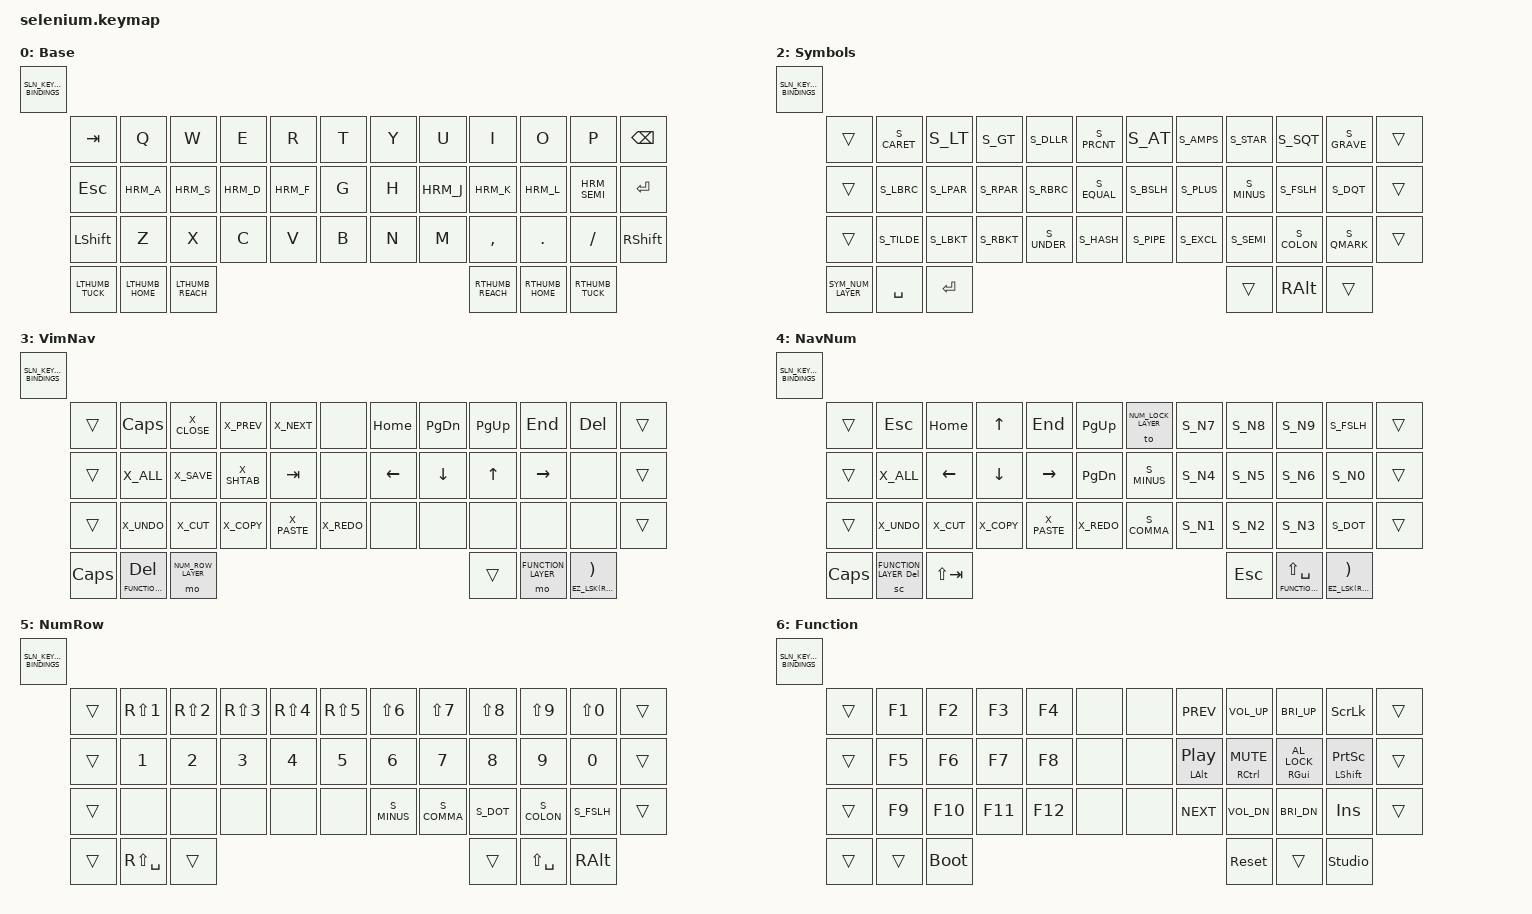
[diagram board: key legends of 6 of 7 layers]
// Selenium keymap:
// https://github.com/OneDeadKey/selenium


/******************************************************************************
 * Layout-specific actions and symbols.
******************************************************************************/

// Uncomment one of the folowing lines if using a non-QWERTY layout:

// #define KB_LAYOUT_QWERTY_LAFAYETTE
// #define KB_LAYOUT_AZERTY
// #define KB_LAYOUT_ERGOL

// Uncomment the folowing line if using a Mac:

// #define MACOS


/******************************************************************************
 * Hold-Taps
******************************************************************************/

// Uncomment one of the folowing lines to pick your preferred hold-tap config:

// #define HT_NONE
// #define HT_THUMB_TAPS
// #define HT_HOME_ROW_MODS  // (default behavior)
// #define HT_TWO_THUMB_KEYS

// Timing is key! Keep the default value if unsure.
// This defines how long (in ms) a hold-tap key with the "tap-preferred" flavor
// must be held to be considered as a modifier or layer shift. These hold-taps
// are the ones that may produce text, including the space-bar and home-row-mods.
// Keep this value high if you struggle wih home-row-mods.

// #define TAPPING_TERM 300

// This defines how quickly (in ms) you need to press and release a hold-tap
// with the "hold-preferred" flavor for it to be considered a tap. These
// hold-taps include the ones that don’t produce text when tapped.
// Keep this value low if you press Enter or Escape by mistake too often.

// #define SHORT_TAPPING_TERM 150

// When tapping then holding the same tap-hold, if the delay between the two
// key presses is lower than `QUICK_TAP`, the tap-hold will hold the tap action
// instead of the hold action. Again, keep the default value if unsure.

// #define QUICK_TAP 200

// For more information on how hold-taps operate, feel free to read ZMK’s docs:
// https://zmk.dev/docs/keymaps/behaviors/hold-tap

/******************************************************************************
 * Other Options
*****************************************************************************/

// Uncomment the following line to plit the num-nav layer in two:
//  - one layer for vim-style navigation (right) and GUI shortcuts (left)
//  - one layer for a full number row + easy access to Shift+Number
//  + Escape under the left thumb (direct access)
// Highly recommended for Vim users, obviously. :-)

// #define VIM_NAVIGATION

// Uncomment the following line to enable shift as a pinky HRM.
// Useful for combined shortcuts, but NOT MEANT to type text!

// #define HRM_SHIFT

// Uncomment the following line to swap Space and Backspace.
// Beware: this increases the typing load of the left thumb.

// #define LEFT_HAND_SPACE


/******************************************************************************
 * Keymap
******************************************************************************/

#include "aliases.h"      // defines symbols and actions
#include "hold_taps.dtsi" // defines thumb keys and homerow mods

/**
 * All keyboard layouts are defined on a 42-key basis, as follows:
 *
 *   Tab   , QWERT , YUIOP , Backspace           LOUT1,  LROW1,  RROW1,  ROUT1
 *   Esc   , ASDFG , HJKL: , Enter        =>     LOUT2,  LROW2,  RROW2,  ROUT2
 *   Shift , ZXCVB , NM<>? , Shift               LOUT3,  LROW3,  RROW3,  ROUT3
 *    LT1, LT2, LT3, RT3, RT2, RT1               LT1, LT2, LT3,  RT3, RT2, RT1
 *
 * Where:
 *
 *   LROW[1-3], RROW[1-3]: keys on the left/right main rows (usually letter/punctuation keys)
 *   LOUT[1-3], ROUT[1-3]: keys on the left/right outer columns (usually special keys)
 *     LT[1-3],   RT[1-3]: keys on the left/right thumb clusters (usually Space or modifiers/layers)
 *
 * Beware: misplacing a comma in the definitions below would break the keymap.
 */

// This macro can be overridden in keymaps if needed.
// Selenium by default only offers keymaps for 3x5 or 3x6 keyboards.
// Redefining this macro allows to add more rows or more columns to the keymap,
// or to add keys between the 2 halves if needed.
#ifndef SLN_KEYMAP_BINDINGS
#define SLN_KEYMAP_BINDINGS(LOUT1,  LROW1,  RROW1,  ROUT1, \
                            LOUT2,  LROW2,  RROW2,  ROUT2, \
                            LOUT3,  LROW3,  RROW3,  ROUT3, \
                            LT1, LT2, LT3,  RT3, RT2, RT1) \
    LOUT1 LROW1 RROW1 ROUT1 \
    LOUT2 LROW2 RROW2 ROUT2 \
    LOUT3 LROW3 RROW3 ROUT3 \
    LT1 LT2 LT3 RT3 RT2 RT1
#endif

/ {
  keymap {
    compatible = "zmk,keymap";

    // 0. Base layer -- keep the QWERTY key codes to use your OS keyboard layout
    //               -- the Space Cadet layer-tap on the right can be replaced by an AltGr/Enter mod-tap
    //               -- adjust the homerow mods with the #define statements above
    base_layer: base_layer {
      display-name = "Base";
      bindings = <SLN_KEYMAP_BINDINGS(                                                                                     \
        &kp TAB    ,  &kp Q  &kp W  &kp E  &kp R  &kp T   ,   &kp Y  &kp U  &kp I     &kp O   &kp P     ,  &kp BACKSPACE , \
        &kp ESCAPE ,  HRM_A  HRM_S  HRM_D  HRM_F  &kp G   ,   &kp H  HRM_J  HRM_K     HRM_L   HRM_SEMI  ,  &kp ENTER     , \
        &kp LSHIFT ,  &kp Z  &kp X  &kp C  &kp V  &kp B   ,   &kp N  &kp M  &kp COMMA &kp DOT &kp FSLH  ,  &kp RSHIFT    , \
               LTHUMB_TUCK , LTHUMB_HOME , LTHUMB_REACH   ,   RTHUMB_REACH , RTHUMB_HOME , RTHUMB_TUCK                     \
      )>;
    };

    // 1. NumLock layer -- NavNum layer that stays on until deactivated without holding key
    num_lock_layer: num_lock_layer {
      display-name = "NumLock";
      bindings = <SLN_KEYMAP_BINDINGS(
        &trans  ,  &kp ESC  &kp HOME &kp UP   &kp END   &kp PG_UP   ,   &to BASE_LAYER S_N7  S_N8  S_N9  S_FSLH  ,  &trans ,
        &trans  ,  S_EQUAL  &kp LEFT &kp DOWN &kp RIGHT &kp PG_DN   ,   S_MINUS        S_N4  S_N5  S_N6  S_N0    ,  &trans ,
        &trans  ,  S_MONEY  S_COLON  S_STAR   S_PLUS    S_PRCNT     ,   S_COMMA        S_N1  S_N2  S_N3  S_DOT   ,  &trans ,
                 &trans , &sc NUM_NAV_LAYER BACKSPACE , &kp (TAB)   ,   &trans , &lt NUM_NAV_LAYER LS(SPACE) , &EZ_SL(SYMBOLS_LAYER)
      )>;
    };

    // 2. Symbols layer -- with Ergol, basically just an AltGr layer with custom thumb keys
    //                  -- can be redefined for non-AltGr layouts such as QWERTY-ANSI
    symbols_layer: symbols_layer {
      display-name = "Symbols";
      bindings = <SLN_KEYMAP_BINDINGS(
        &trans  ,  S_CARET S_LT    S_GT    S_DLLR  S_PRCNT   ,   S_AT    S_AMPS  S_STAR  S_SQT   S_GRAVE  ,  &trans ,
        &trans  ,  S_LBRC  S_LPAR  S_RPAR  S_RBRC  S_EQUAL   ,   S_BSLH  S_PLUS  S_MINUS S_FSLH  S_DQT    ,  &trans ,
        &trans  ,  S_TILDE S_LBKT  S_RBKT  S_UNDER S_HASH    ,   S_PIPE  S_EXCL  S_SEMI  S_COLON S_QMARK  ,  &trans ,
                     SYM_NUM_LAYER , &kp SPACE , &kp ENTER   ,   &trans ,  &kp RALT ,  &trans
      )>;
    };

    // 3. VimNav layer -- HJKL arrow cluster on the right hand
    //                 -- best used along with the NumRow layer
    //                 -- keyboard shortcuts on the left hand are adjusted to the OS layout (Ergol here)
    vim_nav_layer: vim_nav_layer {
      display-name = "VimNav";
      bindings = <SLN_KEYMAP_BINDINGS(
        &trans  ,  &kp CAPS X_CLOSE  X_PREV   X_NEXT    &none     ,   &kp HOME &kp PG_DN &kp PG_UP &kp END   &kp DEL ,  &trans ,
        &trans  ,  X_ALL    X_SAVE   X_SHTAB  &kp TAB   &none     ,   &kp LEFT &kp DOWN  &kp UP    &kp RIGHT &none   ,  &trans ,
        &trans  ,  X_UNDO   X_CUT    X_COPY   X_PASTE   X_REDO    ,   &none    &none     &none     &none     &none   ,  &trans ,
        &kp CAPSLOCK , &lt FUNCTION_LAYER DEL , &mo NUM_ROW_LAYER ,   &trans ,  &mo FUNCTION_LAYER , &EZ_LSK(RALT)
      )>;
    };

    // 4. NavNum layer -- inverted T arrow cluster on the left hand, numpad on the right hand
    //                 -- can be the only extra layer you need if you're not too picky with number+symbols n-grams
    //                 -- keyboard shortcuts on the left hand are adjusted to the OS layout (Ergol here)
    nav_num_layer: nav_num_layer {
      display-name = "NavNum";
      bindings = <SLN_KEYMAP_BINDINGS(
        &trans  ,  &kp ESC  &kp HOME &kp UP   &kp END   &kp PG_UP   ,   &to NUM_LOCK_LAYER S_N7  S_N8  S_N9  S_FSLH  ,  &trans ,
        &trans  ,  X_ALL    &kp LEFT &kp DOWN &kp RIGHT &kp PG_DN   ,   S_MINUS            S_N4  S_N5  S_N6  S_N0    ,  &trans ,
        &trans  ,  X_UNDO   X_CUT    X_COPY   X_PASTE   X_REDO      ,   S_COMMA            S_N1  S_N2  S_N3  S_DOT   ,  &trans ,
              &kp CAPSLOCK , &sc FUNCTION_LAYER DEL , &kp LS(TAB)   ,   &kp ESCAPE , &lt FUNCTION_LAYER , LS(SPACE)  &EZ_LSK(RALT)
      )>;
    };

    // 5. NumRow layer -- bring the numbers to the homerow, keep shift+numbers for shortcuts and symbols
    //                 -- space becomes shift+space, which is a no-break space with some OS layouts (e.g. Ergol)
    //                 -- best used along with the VimNav layer
    num_row_layer: num_row_layer {
      display-name = "NumRow";
      bindings = <SLN_KEYMAP_BINDINGS(
        &trans  ,  &kp RS(N1) &kp RS(N2) &kp RS(N3) &kp RS(N4) &kp RS(N5)   ,   &kp LS(N6) &kp LS(N7) &kp LS(N8) &kp LS(N9) &kp LS(N0)  ,  &trans ,
        &trans  ,  &kp N1     &kp N2     &kp N3     &kp N4     &kp N5       ,   &kp N6     &kp N7     &kp N8     &kp N9     &kp N0      ,  &trans ,
        &trans  ,  &none      &none      &none      &none      &none        ,   S_MINUS    S_COMMA    S_DOT      S_COLON    S_FSLH      ,  &trans ,
                                      &trans , &kp RS(SPACE) , &trans       ,   &trans , &kp LS(SPACE) , &kp RALT
      )>;
    };

    // 6. Function layer -- F1..12 pad on the left hand, HRM on the right hand (with an additional Shift key)
    //                   -- reset and bootloader reset on difficult thumb keys
    //                   -- could be completed with other rare keys
    function_layer: function_layer {
      display-name = "Function";
      bindings = <SLN_KEYMAP_BINDINGS(
        &trans  ,  &kp F1  &kp F2  &kp F3  &kp F4  &none   ,   &none &kp C_PREV     &kp C_VOL_UP     &kp C_BRI_UP        &kp SLCK           ,  &trans ,
        &trans  ,  &kp F5  &kp F6  &kp F7  &kp F8  &none   ,   &none &hrm LALT C_PP &hrm RCTL C_MUTE &hrm RGUI C_AL_LOCK &hrm LSHIFT PSCRN  ,  &trans ,
        &trans  ,  &kp F9  &kp F10 &kp F11 &kp F12 &none   ,   &none &kp C_NEXT     &kp C_VOL_DN     &kp C_BRI_DN        &kp INS            ,  &trans ,
                           &trans , &trans , &bootloader   ,   &sys_reset , &trans , &studio_unlock
      )>;
    };

  };
};

// Some layouts require extra layers to fit on the Quacken.
#ifdef KB_LAYOUT_AZERTY
    #include "extra_layers/azerty.dtsi"
#elif defined KB_LAYOUT_ERGOL && defined HUMMINGBIRD
    #include "extra_layers/ergol_hummingbird.dtsi"
#endif
